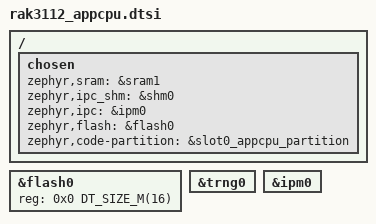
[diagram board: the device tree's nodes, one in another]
/*
 * SPDX-License-Identifier: Apache-2.0
 * Copyright (c) 2026 RAKwireless Technology Limited
 */

#include <espressif/esp32s3/esp32s3_r2.dtsi>
#include <espressif/partitions_0x0_amp_16M.dtsi>

/ {
	chosen {
		zephyr,sram = &sram1;
		zephyr,ipc_shm = &shm0;
		zephyr,ipc = &ipm0;
		zephyr,flash = &flash0;
		zephyr,code-partition = &slot0_appcpu_partition;
	};
};

&flash0 {
	reg = <0x0 DT_SIZE_M(16)>;
};

&trng0 {
	status = "okay";
};

&ipm0 {
	status = "okay";
};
